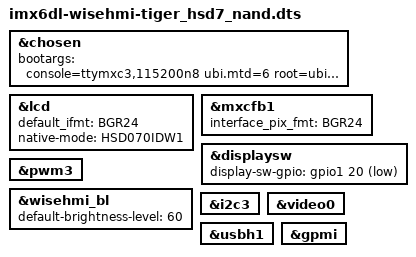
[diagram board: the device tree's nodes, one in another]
#include "imx6dl-wisehmi.dts"

&chosen{
       bootargs = "console=ttymxc3,115200n8 ubi.mtd=6 root=ubi0:rootfs rootfstype=ubifs fm_autoconvert=1 rootwait rw  mtdparts=gpmi-nand:64m(spl),1m(uboot),512k(env),512k(dtb),6m(kernel),58m(initramfs),-(rootfs) lpj=7905280 initroot=10:none,initramfs,/startup/run";
};

&lcd {
	default_ifmt = "BGR24";
	native-mode = <&HSD070IDW1>;
 };

&mxcfb1 {
	interface_pix_fmt = "BGR24";
}; 

&displaysw{
	display-sw-gpio = <&gpio1 20 GPIO_ACTIVE_LOW>;
};

&pwm3 {
	status = "okay";
};

&wisehmi_bl {
	default-brightness-level = <60>; 
	status = "okay";
};

&i2c3 {
	status = "okay";
};

&video0{
	status = "okay";
};

&usbh1 {
	status = "okay";
};

&gpmi {
	status = "okay";
};
